# BlueNRG_LPF register map
File version: 1.0
CPU: CM0+ r0p0, little endian, no MPU, no FPU, 2 interrupt priority bits
Registers are 32-bit, read-write, reset 0x0 unless marked. A register's access mark holds for its fields unless they carry their own. Offsets are from the block's base; [hi:lo] are bit positions.

## RTC — Real-time clock
Base 0x40004000
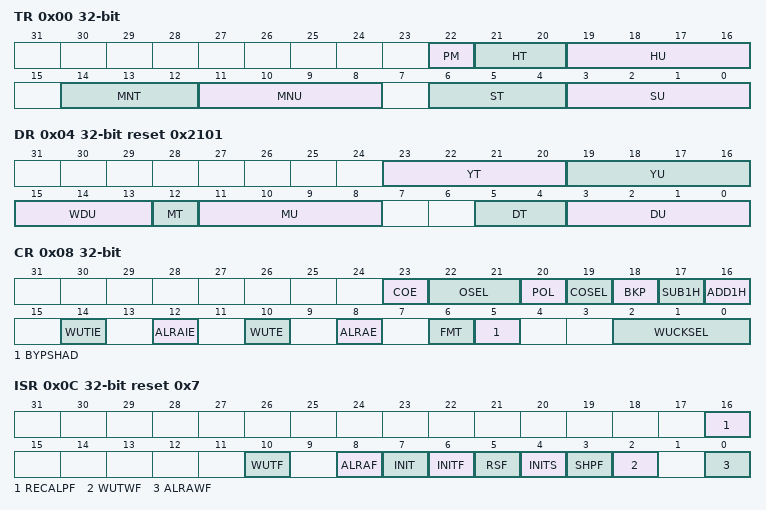
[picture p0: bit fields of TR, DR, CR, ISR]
0x00 TR — time register
  [22] PM — AM/PM notation
  [21:20] HT — Hour tens in BCD format
  [19:16] HU — Hour units in BCD format
  [14:12] MNT — Minute tens in BCD format
  [11:8] MNU — Minute units in BCD format
  [6:4] ST — Second tens in BCD format
  [3:0] SU — Second units in BCD format
0x04 DR reset 0x2101 — date register
  [23:20] YT — Year tens in BCD format
  [19:16] YU — Year units in BCD format
  [15:13] WDU — Week day units
  [12] MT — Month tens in BCD format
  [11:8] MU — Month units in BCD format
  [5:4] DT — Date tens in BCD format
  [3:0] DU — Date units in BCD format
0x08 CR — control register
  [23] COE — Calibration output enable
  [22:21] OSEL — Output selection
  [20] POL — Output polarity
  [19] COSEL — Calibration output selection
  [18] BKP — Backup
  [17] SUB1H — Subtract 1 hour (winter time change)
  [16] ADD1H — Add 1 hour (summer time change)
  [14] WUTIE — Wakeup timer interrupt enable
  [12] ALRAIE — Alarm A interrupt enable
  [10] WUTE — Wakeup timer enable
  [8] ALRAE — Alarm A enable
  [6] FMT — Hour format
  [5] BYPSHAD — Bypass the shadow registers
  [2:0] WUCKSEL — Wakeup clock selection
0x0C ISR reset 0x7 — initialization and status register
  [16] RECALPF ro — Recalibration pending Flag
  [10] WUTF — Wakeup timer flag
  [8] ALRAF — Alarm A flag
  [7] INIT — Initialization mode
  [6] INITF ro — Initialization flag
  [5] RSF — Registers synchronization flag
  [4] INITS ro — Initialization status flag
  [3] SHPF — Shift operation pending
  [2] WUTWF ro — Wakeup timer write flag
  [0] ALRAWF ro — Alarm A write flag
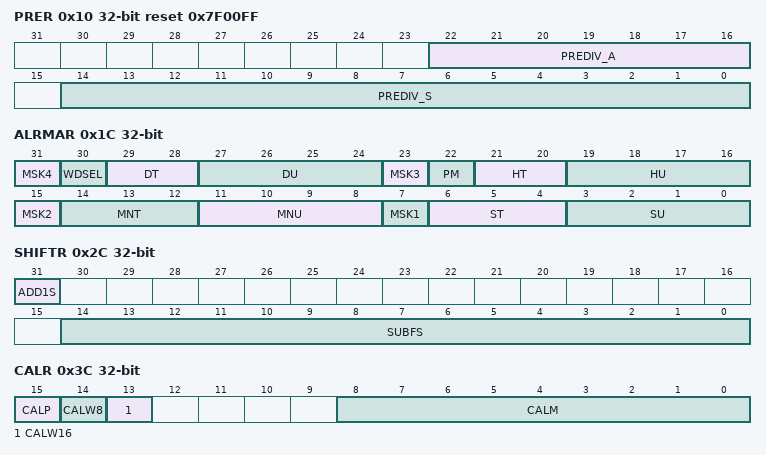
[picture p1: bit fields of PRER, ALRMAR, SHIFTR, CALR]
0x10 PRER reset 0x7F00FF — prescaler register
  [22:16] PREDIV_A — Asynchronous prescaler factor
  [14:0] PREDIV_S — Synchronous prescaler factor
0x14 WUTR reset 0xFFFF — wakeup timer register
  [15:0] WUT — Wakeup auto-reload prescaler bits
0x1C ALRMAR — alarm A register
  [31] MSK4 — Alarm A date mask
  [30] WDSEL — Week day selection
  [29:28] DT — Date tens in BCD format
  [27:24] DU — Date units or day in BCD format
  [23] MSK3 — Alarm A hours mask
  [22] PM — AM/PM notation
  [21:20] HT — Hour tens in BCD format
  [19:16] HU — Hour units in BCD format
  [15] MSK2 — Alarm A minutes mask
  [14:12] MNT — Minute tens in BCD format
  [11:8] MNU — Minute units in BCD format
  [7] MSK1 — Alarm A seconds mask
  [6:4] ST — Second tens in BCD format
  [3:0] SU — Second units in BCD format
0x24 WPR wo — write protection register
  [7:0] KEY — Write protection key
0x28 SSR ro — sub second register
  [15:0] SS — Sub second value
0x2C SHIFTR wo — shift control register
  [31] ADD1S — Add one second
  [14:0] SUBFS — Subtract a fraction of A second
0x3C CALR — calibration register
  [15] CALP — Increase frequency of RTC by 488.5 ppm
  [14] CALW8 — Use an 8-second calibration cycle period
  [13] CALW16 — Use a 16-second calibration cycle period
  [8:0] CALM — Calibration minus
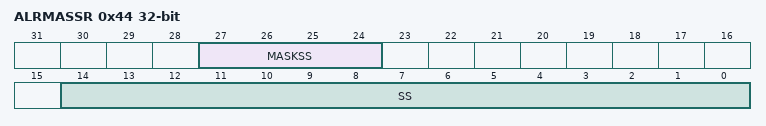
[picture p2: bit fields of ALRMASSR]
0x44 ALRMASSR — alarm A sub second register
  [27:24] MASKSS — Mask the most-significant bits starting at this bit
  [14:0] SS — Sub seconds value
0x50 BKP0R — backup register 0
  [31:0] BKP
0x54 BKP1R — backup register 1
  [31:0] BKP

## SPI3 — Serial peripheral interface/Inter-IC sound
Base 0x41007000
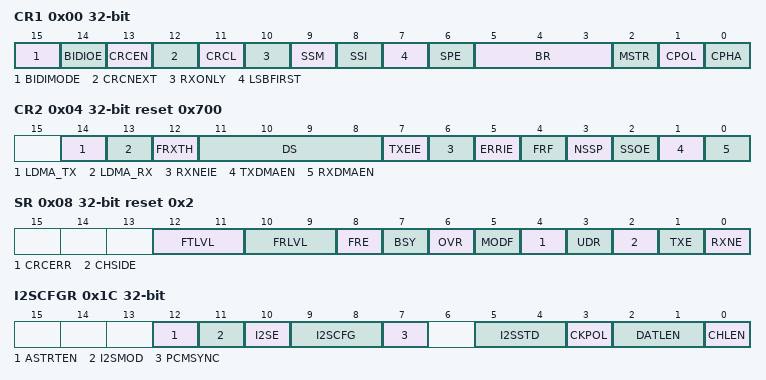
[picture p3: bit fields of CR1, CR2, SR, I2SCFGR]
0x00 CR1 — control register 1
  [15] BIDIMODE — Bidirectional data mode enable
  [14] BIDIOE — Output enable in bidirectional mode
  [13] CRCEN — Hardware CRC calculation enable
  [12] CRCNEXT — CRC transfer next
  [11] CRCL — CRC length
  [10] RXONLY — Receive only
  [9] SSM — Software slave management
  [8] SSI — Internal slave select
  [7] LSBFIRST — Frame format
  [6] SPE — SPI enable
  [5:3] BR — Baud rate control
  [2] MSTR — Master selection
  [1] CPOL — Clock polarity
  [0] CPHA — Clock phase
0x04 CR2 reset 0x700 — control register 2
  [14] LDMA_TX
  [13] LDMA_RX
  [12] FRXTH — FIFO reception threshold
  [11:8] DS — Data size
  [7] TXEIE — Tx buffer empty interrupt enable
  [6] RXNEIE — RX buffer not empty interrupt enable
  [5] ERRIE — Error interrupt enable
  [4] FRF — Frame format
  [3] NSSP — NSs pulse management
  [2] SSOE — Ss output enable
  [1] TXDMAEN — Tx buffer DMA enable
  [0] RXDMAEN — Rx buffer DMA enable
0x08 SR reset 0x2 — status register
  [12:11] FTLVL ro — FIFO transmission level
  [10:9] FRLVL ro — FIFO reception level
  [8] FRE ro
  [7] BSY ro — Busy flag
  [6] OVR ro — Overrun flag
  [5] MODF ro — Mode fault
  [4] CRCERR — CRC error flag
  [3] UDR ro — Underrun flag
  [2] CHSIDE ro — Channel side
  [1] TXE ro — Transmit buffer empty
  [0] RXNE ro — Receive buffer not empty
0x0C DR — data register
  [15:0] DR — Data register
0x10 CRCPR reset 0x7 — CRC polynomial register
  [15:0] CRCPOLY
0x14 RXCRCR ro — RX CRC register
  [15:0] RXCRC
0x18 TXCRCR ro — TX CRC register
  [15:0] TXCRC
0x1C I2SCFGR
  [12] ASTRTEN — Asynchronous start enable
  [11] I2SMOD — I2s mode selection
  [10] I2SE — I2s enable
  [9:8] I2SCFG — I2s configuration mode
  [7] PCMSYNC — PCM frame synchronization
  [5:4] I2SSTD — I2s standard selection
  [3] CKPOL — Steady state clock polarity
  [2:1] DATLEN — Data length to be transferred
  [0] CHLEN — Channel length (number of bits per audio channel)
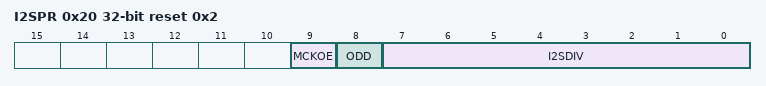
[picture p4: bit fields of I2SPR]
0x20 I2SPR reset 0x2
  [9] MCKOE — Master clock output enable
  [8] ODD — Odd factor for the prescaler
  [7:0] I2SDIV — I2s linear prescaler
